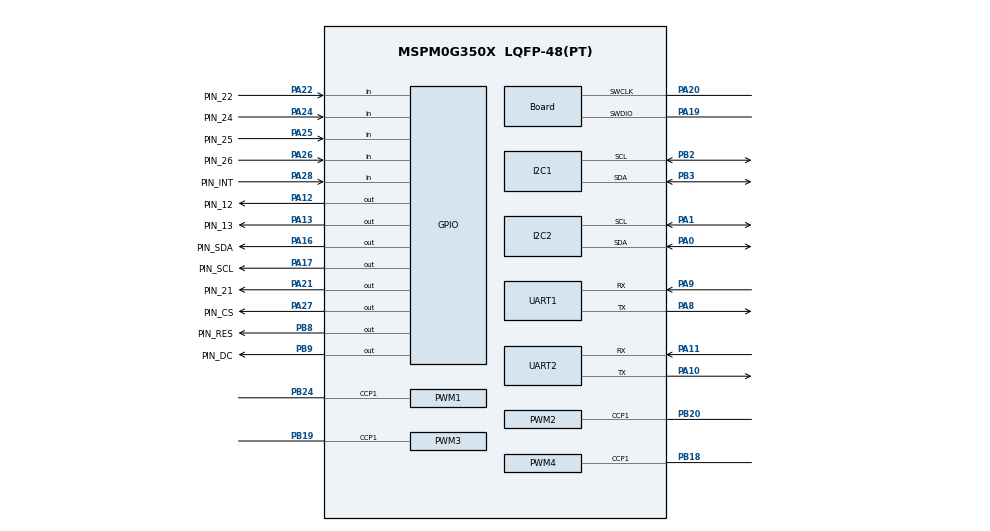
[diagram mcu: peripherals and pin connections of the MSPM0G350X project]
/**
 * @cliArgs --device "MSPM0G350X" --part "Default" --package "LQFP-48(PT)" --product "mspm0_sdk@2.04.00.06"
 * @versions {"tool":"1.23.1+4034"}
 */

/**
 * Import the modules used in this configuration.
 */
const GPIO   = scripting.addModule("/ti/driverlib/GPIO", {}, false);
const GPIO1  = GPIO.addInstance();
const GPIO2  = GPIO.addInstance();
const GPIO3  = GPIO.addInstance();
const GPIO4  = GPIO.addInstance();
const GPIO5  = GPIO.addInstance();
const I2C    = scripting.addModule("/ti/driverlib/I2C", {}, false);
const I2C1   = I2C.addInstance();
const I2C2   = I2C.addInstance();
const PWM    = scripting.addModule("/ti/driverlib/PWM", {}, false);
const PWM1   = PWM.addInstance();
const PWM2   = PWM.addInstance();
const PWM3   = PWM.addInstance();
const PWM4   = PWM.addInstance();
const SYSCTL = scripting.addModule("/ti/driverlib/SYSCTL");
const UART   = scripting.addModule("/ti/driverlib/UART", {}, false);
const UART1  = UART.addInstance();
const UART2  = UART.addInstance();

/**
 * Write custom configuration values to the imported modules.
 */
const divider7       = system.clockTree["PLL_PDIV"];
divider7.divideValue = 2;

const divider9       = system.clockTree["UDIV"];
divider9.divideValue = 2;

const gate7  = system.clockTree["MFCLKGATE"];
gate7.enable = true;

const multiplier2         = system.clockTree["PLL_QDIV"];
multiplier2.multiplyValue = 5;

const mux8       = system.clockTree["HSCLKMUX"];
mux8.inputSelect = "HSCLKMUX_SYSPLL2X";

GPIO1.$name                         = "GPIO_OLED";
GPIO1.associatedPins.create(5);
GPIO1.associatedPins[0].$name       = "PIN_RES";
GPIO1.associatedPins[0].pin.$assign = "PB8";
GPIO1.associatedPins[1].$name       = "PIN_SCL";
GPIO1.associatedPins[1].pin.$assign = "PA17";
GPIO1.associatedPins[2].$name       = "PIN_SDA";
GPIO1.associatedPins[2].pin.$assign = "PA16";
GPIO1.associatedPins[3].$name       = "PIN_DC";
GPIO1.associatedPins[3].pin.$assign = "PB9";
GPIO1.associatedPins[4].$name       = "PIN_CS";
GPIO1.associatedPins[4].pin.$assign = "PA27";

const Board                       = scripting.addModule("/ti/driverlib/Board", {}, false);
Board.peripheral.$assign          = "DEBUGSS";
Board.peripheral.swclkPin.$assign = "PA20";
Board.peripheral.swdioPin.$assign = "PA19";

GPIO2.$name                         = "LED";
GPIO2.port                          = "PORTA";
GPIO2.associatedPins.create(2);
GPIO2.associatedPins[0].$name       = "PIN_13";
GPIO2.associatedPins[0].pin.$assign = "PA13";
GPIO2.associatedPins[1].$name       = "PIN_12";
GPIO2.associatedPins[1].pin.$assign = "PA12";

GPIO3.$name                         = "GPIO_KEYS";
GPIO3.port                          = "PORTA";
GPIO3.associatedPins.create(4);
GPIO3.associatedPins[0].$name       = "PIN_26";
GPIO3.associatedPins[0].direction   = "INPUT";
GPIO3.associatedPins[0].interruptEn = true;
GPIO3.associatedPins[0].polarity    = "RISE";
GPIO3.associatedPins[0].pin.$assign = "PA26";
GPIO3.associatedPins[1].$name       = "PIN_25";
GPIO3.associatedPins[1].direction   = "INPUT";
GPIO3.associatedPins[1].interruptEn = true;
GPIO3.associatedPins[1].polarity    = "RISE";
GPIO3.associatedPins[1].pin.$assign = "PA25";
GPIO3.associatedPins[2].direction   = "INPUT";
GPIO3.associatedPins[2].$name       = "PIN_24";
GPIO3.associatedPins[2].interruptEn = true;
GPIO3.associatedPins[2].polarity    = "RISE";
GPIO3.associatedPins[2].pin.$assign = "PA24";
GPIO3.associatedPins[3].$name       = "PIN_22";
GPIO3.associatedPins[3].direction   = "INPUT";
GPIO3.associatedPins[3].interruptEn = true;
GPIO3.associatedPins[3].polarity    = "RISE";
GPIO3.associatedPins[3].pin.$assign = "PA22";

GPIO4.$name                         = "BEEP";
GPIO4.port                          = "PORTA";
GPIO4.associatedPins[0].$name       = "PIN_21";
GPIO4.associatedPins[0].pin.$assign = "PA21";

GPIO5.$name                               = "GPIO_MPU6050";
GPIO5.associatedPins[0].$name             = "PIN_INT";
GPIO5.associatedPins[0].direction         = "INPUT";
GPIO5.associatedPins[0].internalResistor  = "PULL_UP";
GPIO5.associatedPins[0].interruptEn       = true;
GPIO5.associatedPins[0].interruptPriority = "1";
GPIO5.associatedPins[0].polarity          = "FALL";
GPIO5.associatedPins[0].pin.$assign       = "PA28";

I2C1.$name                             = "I2C_BUS";
I2C1.basicEnableController             = true;
I2C1.basicControllerStandardBusSpeed   = "Fast";
I2C1.peripheral.$assign                = "I2C1";
I2C1.peripheral.sdaPin.$assign         = "PB3";
I2C1.peripheral.sclPin.$assign         = "PB2";
I2C1.sdaPinConfig.$name                = "ti_driverlib_gpio_GPIOPinGeneric0";
I2C1.sdaPinConfig.hideOutputInversion  = scripting.forceWrite(false);
I2C1.sdaPinConfig.onlyInternalResistor = scripting.forceWrite(false);
I2C1.sdaPinConfig.passedPeripheralType = scripting.forceWrite("Digital");
I2C1.sclPinConfig.$name                = "ti_driverlib_gpio_GPIOPinGeneric1";
I2C1.sclPinConfig.hideOutputInversion  = scripting.forceWrite(false);
I2C1.sclPinConfig.onlyInternalResistor = scripting.forceWrite(false);
I2C1.sclPinConfig.passedPeripheralType = scripting.forceWrite("Digital");

I2C2.$name                             = "I2C_MPU6050";
I2C2.basicEnableController             = true;
I2C2.basicControllerStandardBusSpeed   = "Fast";
I2C2.peripheral.$assign                = "I2C0";
I2C2.peripheral.sdaPin.$assign         = "PA0";
I2C2.peripheral.sclPin.$assign         = "PA1";
I2C2.sdaPinConfig.hideOutputInversion  = scripting.forceWrite(false);
I2C2.sdaPinConfig.onlyInternalResistor = scripting.forceWrite(false);
I2C2.sdaPinConfig.passedPeripheralType = scripting.forceWrite("Digital");
I2C2.sdaPinConfig.$name                = "ti_driverlib_gpio_GPIOPinGeneric8";
I2C2.sclPinConfig.hideOutputInversion  = scripting.forceWrite(false);
I2C2.sclPinConfig.onlyInternalResistor = scripting.forceWrite(false);
I2C2.sclPinConfig.passedPeripheralType = scripting.forceWrite("Digital");
I2C2.sclPinConfig.$name                = "ti_driverlib_gpio_GPIOPinGeneric9";

PWM1.$name                              = "PWM_R1";
PWM1.timerStartTimer                    = true;
PWM1.ccIndex                            = [1];
PWM1.ccp1PinConfig.direction            = scripting.forceWrite("OUTPUT");
PWM1.ccp1PinConfig.hideOutputInversion  = scripting.forceWrite(false);
PWM1.ccp1PinConfig.onlyInternalResistor = scripting.forceWrite(false);
PWM1.ccp1PinConfig.passedPeripheralType = scripting.forceWrite("Digital");
PWM1.ccp1PinConfig.$name                = "ti_driverlib_gpio_GPIOPinGeneric3";
PWM1.peripheral.$assign                 = "TIMG12";
PWM1.peripheral.ccp1Pin.$assign         = "PB24";
PWM1.PWM_CHANNEL_1.$name                = "ti_driverlib_pwm_PWMTimerCC0";
PWM1.PWM_CHANNEL_1.initVal              = "HIGH";

PWM2.$name                              = "PWM_R2";
PWM2.timerStartTimer                    = true;
PWM2.ccIndex                            = [1];
PWM2.ccp1PinConfig.direction            = scripting.forceWrite("OUTPUT");
PWM2.ccp1PinConfig.hideOutputInversion  = scripting.forceWrite(false);
PWM2.ccp1PinConfig.onlyInternalResistor = scripting.forceWrite(false);
PWM2.ccp1PinConfig.passedPeripheralType = scripting.forceWrite("Digital");
PWM2.ccp1PinConfig.$name                = "ti_driverlib_gpio_GPIOPinGeneric4";
PWM2.peripheral.$assign                 = "TIMA0";
PWM2.peripheral.ccp1Pin.$assign         = "PB20";
PWM2.PWM_CHANNEL_1.$name                = "ti_driverlib_pwm_PWMTimerCC1";
PWM2.PWM_CHANNEL_1.initVal              = "HIGH";

PWM3.$name                              = "PWM_L1";
PWM3.ccIndex                            = [1];
PWM3.timerStartTimer                    = true;
PWM3.ccp1PinConfig.direction            = scripting.forceWrite("OUTPUT");
PWM3.ccp1PinConfig.hideOutputInversion  = scripting.forceWrite(false);
PWM3.ccp1PinConfig.onlyInternalResistor = scripting.forceWrite(false);
PWM3.ccp1PinConfig.passedPeripheralType = scripting.forceWrite("Digital");
PWM3.ccp1PinConfig.$name                = "ti_driverlib_gpio_GPIOPinGeneric5";
PWM3.peripheral.$assign                 = "TIMG8";
PWM3.peripheral.ccp1Pin.$assign         = "PB19";
PWM3.PWM_CHANNEL_1.$name                = "ti_driverlib_pwm_PWMTimerCC2";
PWM3.PWM_CHANNEL_1.initVal              = "HIGH";

PWM4.$name                              = "PWM_L2";
PWM4.timerStartTimer                    = true;
PWM4.ccIndex                            = [1];
PWM4.ccp1PinConfig.direction            = scripting.forceWrite("OUTPUT");
PWM4.ccp1PinConfig.hideOutputInversion  = scripting.forceWrite(false);
PWM4.ccp1PinConfig.onlyInternalResistor = scripting.forceWrite(false);
PWM4.ccp1PinConfig.passedPeripheralType = scripting.forceWrite("Digital");
PWM4.ccp1PinConfig.$name                = "ti_driverlib_gpio_GPIOPinGeneric6";
PWM4.peripheral.$assign                 = "TIMA1";
PWM4.peripheral.ccp1Pin.$assign         = "PB18";
PWM4.PWM_CHANNEL_1.$name                = "ti_driverlib_pwm_PWMTimerCC3";
PWM4.PWM_CHANNEL_1.initVal              = "HIGH";

SYSCTL.forceDefaultClkConfig = true;
SYSCTL.clockTreeEn           = true;
scripting.suppress("For best practices when the CPUCLK is running at 32MHz and above, clear the flash status bit using DL_FlashCTL_executeClearStatus\\(\\) before executing any flash operation\\. Otherwise there may be false positives\\.", SYSCTL);

UART1.$name                    = "UART_0";
UART1.uartClkSrc               = "MFCLK";
UART1.enabledInterrupts        = ["RX"];
UART1.peripheral.$assign       = "UART1";
UART1.peripheral.rxPin.$assign = "PA9";
UART1.peripheral.txPin.$assign = "PA8";
UART1.txPinConfig.$name        = "ti_driverlib_gpio_GPIOPinGeneric2";
UART1.rxPinConfig.$name        = "ti_driverlib_gpio_GPIOPinGeneric7";

UART2.$name                    = "UART_1";
UART2.uartClkSrc               = "MFCLK";
UART2.enabledInterrupts        = ["RX"];
UART2.peripheral.rxPin.$assign = "PA11";
UART2.peripheral.txPin.$assign = "PA10";
UART2.txPinConfig.$name        = "ti_driverlib_gpio_GPIOPinGeneric11";
UART2.rxPinConfig.$name        = "ti_driverlib_gpio_GPIOPinGeneric12";

const ProjectConfig              = scripting.addModule("/ti/project_config/ProjectConfig", {}, false);
ProjectConfig.migrationCondition = true;

/**
 * Pinmux solution for unlocked pins/peripherals. This ensures that minor changes to the automatic solver in a future
 * version of the tool will not impact the pinmux you originally saw.  These lines can be completely deleted in order to
 * re-solve from scratch.
 */
UART2.peripheral.$suggestSolution = "UART0";
